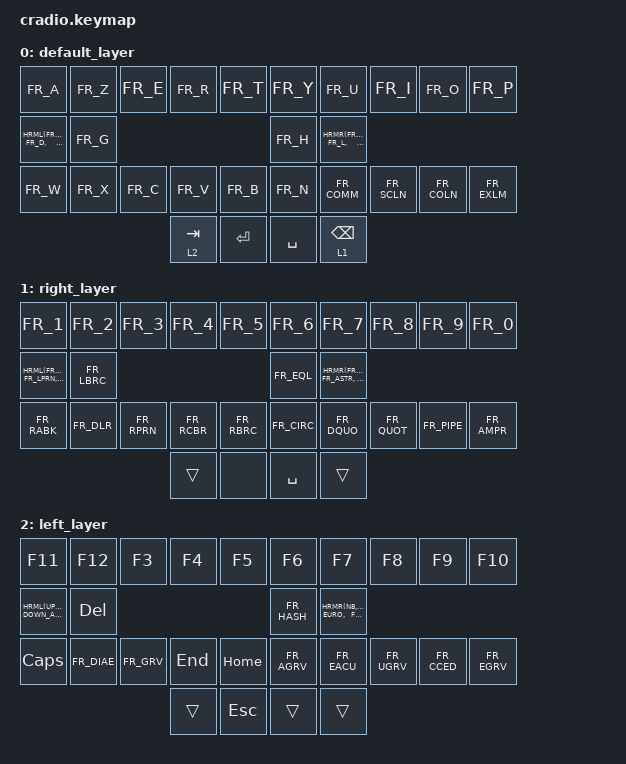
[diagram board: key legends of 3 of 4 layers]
// Copyright (c) 2022 The ZMK Contributors
// SPDX-License-Identifier: MIT

#include <behaviors.dtsi>
#include <dt-bindings/zmk/keys.h>
#include <dt-bindings/zmk/bt.h>
#include "keymap_french.h"

// Home row mods macro
#define HRML(k1,k2,k3,k4) &ht LSHFT k1  &ht LALT k2  &ht LCTRL k3  &ht LGUI k4
#define HRMR(k1,k2,k3,k4) &ht RGUI k1  &ht RCTRL k2  &ht RALT k3  &ht RSHFT k4

/ {
    behaviors {
        ht: hold_tap {
            compatible = "zmk,behavior-hold-tap";
            #binding-cells = <2>;
            flavor = "tap-preferred";
            tapping-term-ms = <220>;
            quick-tap-ms = <150>;
            require-prior-idle-ms = <100>;
            bindings = <&kp>, <&kp>;
        };
    };

    conditional_layers {
        compatible = "zmk,conditional-layers";
        tri_layer {
            if-layers = <1 2>; 
            then-layer = <3>;
        };
    };

    keymap {
        compatible = "zmk,keymap";
        default_layer {
            bindings = <
        //╭──────────┬──────────┬──────────┬──────────┬──────────╮   ╭──────────┬──────────┬──────────┬──────────┬──────────╮
        //│  A       │   Z      │  E       │  R       │  T       │   │  Y       │  U       │  I       │  O       │  P       │
            &kp FR_A   &kp FR_Z   &kp FR_E  &kp FR_R   &kp FR_T       &kp FR_Y   &kp FR_U    &kp FR_I   &kp FR_O   &kp FR_P
        //├──────────┼──────────┼──────────┼──────────┼──────────┤   ├──────────┼──────────┼──────────┼──────────┼──────────┤
        //│  Q       │  S       │  D       │  F       │  G       │   │  H       │  J       │  K       │  L       │ M        │
            HRML(FR_Q,   FR_S,    FR_D,       FR_F)     &kp FR_G       &kp FR_H   HRMR(FR_J,    FR_K,     FR_L,       FR_M)
        //├──────────┼──────────┼──────────┼──────────┼──────────┤   ├──────────┼──────────┼──────────┼──────────┼──────────┤
        //│  W       │  X       │  C       │  V       │  B       │   │  N       │  , ?     │   ; .    │ : /      │ ! §      │
            &kp FR_W   &kp FR_X   &kp FR_C &kp FR_V &kp FR_B           &kp FR_N &kp FR_COMM &kp FR_SCLN &kp FR_COLN &kp FR_EXLM
        //╰──────────┴──────────┴──────────┼──────────┼──────────┤   ├──────────┼──────────┼──────────┴──────────┴──────────╯
                                            &lt 2 TAB   &kp ENTER     &kp SPACE  &lt 1 BSPC
        //                                 ╰──────────┴──────────╯   ╰──────────┴──────────╯
            >;
        };

        right_layer {
            bindings = <
        //╭──────────┬──────────┬──────────┬──────────┬──────────╮   ╭──────────┬──────────┬──────────┬──────────┬──────────╮
        //│ 1        │  2       │  3       │  4       │   5      │   │ 6        │ 7        │ 8        │ 9        │  0       │
            &kp FR_1   &kp FR_2  &kp FR_3   &kp FR_4   &kp FR_5         &kp FR_6  &kp FR_7  &kp FR_8   &kp FR_9   &kp FR_0
        //├──────────┼──────────┼──────────┼──────────┼──────────┤   ├──────────┼──────────┼──────────┼──────────┼──────────┤
        //│ <        │  \       │  (       │  {       │  [       │   │ =        │ +        │ -        │ *        │  %       │
         HRML(FR_LABK,   FR_BSLS,  FR_LPRN,  FR_LCBR)   &kp FR_LBRC   &kp FR_EQL HRMR(FR_PLUS, FR_MINS, FR_ASTR,    FR_PERC)
        //├──────────┼──────────┼──────────┼──────────┼──────────┤   ├──────────┼──────────┼──────────┼──────────┼──────────┤
        //│  >       │  $       │  )       │  }       │  ]       │   │     ^    │     "    │    '     │     |    │    &     │
           &kp FR_RABK &kp FR_DLR &kp FR_RPRN &kp FR_RCBR &kp FR_RBRC &kp FR_CIRC &kp FR_DQUO &kp FR_QUOT &kp FR_PIPE &kp FR_AMPR
        //╰──────────┴──────────┴──────────┼──────────┼──────────┤   ├──────────┼──────────┼──────────┴──────────┴──────────╯
                                             &trans     &none        &kp SPACE     &trans
        //                                 ╰──────────┴──────────╯   ╰──────────┴──────────╯
            >;
        };

        left_layer {
            bindings = <
        //╭──────────┬──────────┬──────────┬──────────┬──────────╮   ╭──────────┬──────────┬──────────┬──────────┬──────────╮
        //│   F11    │   F12    │  F3      │  F4      │   F5     │   │   F6     │  F7      │   F8     │  F9      │  F10     │
            &kp F11     &kp F12   &kp F3     &kp F4     &kp F5         &kp F6     &kp F7     &kp F8      &kp F9     &kp F10
        //├──────────┼──────────┼──────────┼──────────┼──────────┤   ├──────────┼──────────┼──────────┼──────────┼──────────┤
        //│ UARW     │  LARW    │  DARW    │  RARW    │  DELETE  │   │  #       │  _       │  @       │  €       │  ~       │
         HRML(UP_ARROW, LEFT_ARROW, DOWN_ARROW, RIGHT_ARROW) &kp DEL  &kp FR_HASH HRMR(N8, FR_AT,  FR_EURO,   FR_TILD)
        //├──────────┼──────────┼──────────┼──────────┼──────────┤   ├──────────┼──────────┼──────────┼──────────┼──────────┤
        //│   CAPS   │     ¨    │      `   │   FIN    │   HOME   │   │  à       │  é       │  ù       │  ç       │    è     │
            &kp CAPS  &kp FR_DIAE &kp FR_GRV  &kp END   &kp HOME    &kp FR_AGRV &kp FR_EACU &kp FR_UGRV &kp FR_CCED &kp FR_EGRV
        //╰──────────┴──────────┴──────────┼──────────┼──────────┤   ├──────────┼──────────┼──────────┴──────────┴──────────╯
                                             &trans     &kp ESC         &trans     &trans
        //                                 ╰──────────┴──────────╯   ╰──────────┴──────────╯
            >;
        };

        tri_layer {
            bindings = <
        //╭──────────┬──────────┬──────────┬──────────┬──────────╮   ╭──────────┬──────────┬──────────┬──────────┬──────────╮
        //│ MUTE     │  V_DOWN  │    V_UP  │ BRI_DOWN │   BRI_UP │   │  IMPECR  │     F1   │   F2     │          │   PIP    │
        &kp C_MUTE &kp C_VOL_DN &kp C_VOL_UP &kp C_BRI_DN &kp C_BRI_UP  &kp PSCRN   &kp F1     &kp F2   &none      &kp C_PIP
        //├──────────┼──────────┼──────────┼──────────┼──────────┤   ├──────────┼──────────┼──────────┼──────────┼──────────┤
        //│          │          │          │          │          │   │          │          │          │          |          |
            &none        &none     &none     &none     &none          &none      &none       &none      &none      &none
        //├──────────┼──────────┼──────────┼──────────┼──────────┤   ├──────────┼──────────┼──────────┼──────────┼──────────┤
        //│  RESET   │ CLEAR BT │          │          │          │   │          │          │          │          │BOOTLOADER│
           &sys_reset  &bt BT_CLR  &none      &none     &none          &none       &none      &none      &none    &bootloader
        //╰──────────┴──────────┴──────────┼──────────┼──────────┤   ├──────────┼──────────┼──────────┴──────────┴──────────╯
                                             &trans     &none         &trans     &trans
        //                                 ╰──────────┴──────────╯   ╰──────────┴──────────╯
            >;
        };
    };
};
